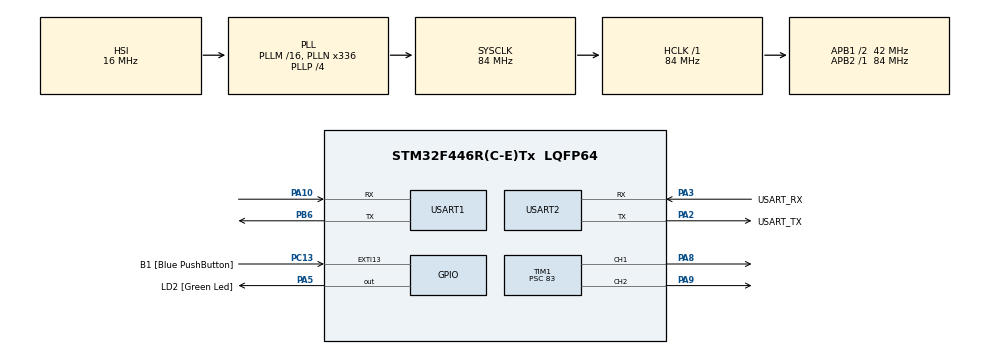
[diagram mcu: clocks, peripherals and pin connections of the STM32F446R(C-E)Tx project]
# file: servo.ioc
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Mcu.Family=STM32F4
Mcu.Name=STM32F446R(C-E)Tx
Mcu.Package=LQFP64
NVIC.PriorityGroup=NVIC_PRIORITYGROUP_0
PA10.Mode=Asynchronous
PA10.Signal=USART1_RX
PA13.GPIO_Label=TMS
PA13.Mode=Serial_Wire
PA13.Signal=SYS_JTMS-SWDIO
PA14.GPIO_Label=TCK
PA14.Mode=Serial_Wire
PA14.Signal=SYS_JTCK-SWCLK
PA2.GPIO_Label=USART_TX
PA2.GPIO_PuPd=GPIO_NOPULL
PA2.Mode=Asynchronous
PA2.Signal=USART2_TX
PA3.GPIO_Label=USART_RX
PA3.Mode=Asynchronous
PA3.Signal=USART2_RX
PA5.GPIO_Label=LD2 [Green Led]
PA5.Signal=GPIO_Output
PA8.Signal=S_TIM1_CH1
PA9.Signal=S_TIM1_CH2
PB3.GPIO_Label=SWO
PB3.Signal=SYS_JTDO-SWO
PB6.GPIO_PuPd=GPIO_PULLUP
PB6.Mode=Asynchronous
PB6.Signal=USART1_TX
PC13.GPIO_Label=B1 [Blue PushButton]
PC13.GPIO_ModeDefaultEXTI=GPIO_MODE_IT_FALLING
PC13.Signal=GPXTI13
PC14-OSC32_IN.Mode=LSE-External-Oscillator
PC14-OSC32_IN.Signal=RCC_OSC32_IN
PC15-OSC32_OUT.Mode=LSE-External-Oscillator
PC15-OSC32_OUT.Signal=RCC_OSC32_OUT
PH0-OSC_IN.Mode=HSE-External-Oscillator
PH0-OSC_IN.Signal=RCC_OSC_IN
PH1-OSC_OUT.Mode=HSE-External-Oscillator
PH1-OSC_OUT.Signal=RCC_OSC_OUT
ProjectManager.HeapSize=0x200
ProjectManager.StackSize=0x400
ProjectManager.TargetToolchain=STM32CubeIDE
RCC.48MHZClocksFreq_Value=84000000
RCC.AHBFreq_Value=84000000
RCC.APB1CLKDivider=RCC_HCLK_DIV2
RCC.APB1Freq_Value=42000000
RCC.APB1TimFreq_Value=84000000
RCC.APB2Freq_Value=84000000
RCC.APB2TimFreq_Value=84000000
RCC.CortexFreq_Value=84000000
RCC.FLatency-AdvancedSettings=FLASH_LATENCY_2
RCC.HCLKFreq_Value=84000000
RCC.HSE_VALUE=8000000
RCC.HSI_VALUE=16000000
RCC.PLLN=336
RCC.PLLP=RCC_PLLP_DIV4
RCC.SYSCLKFreq_VALUE=84000000
RCC.SYSCLKSource=RCC_SYSCLKSOURCE_PLLCLK
RCC.USBFreq_Value=168000000
RCC.VCOOutputFreq_Value=336000000
SH.S_TIM1_CH1.0=TIM1_CH1,PWM Generation1 CH1
SH.S_TIM1_CH2.0=TIM1_CH2,PWM Generation2 CH2
TIM1.Channel-PWM\ Generation1\ CH1=TIM_CHANNEL_1
TIM1.Channel-PWM\ Generation2\ CH2=TIM_CHANNEL_2
TIM1.Period=19999
TIM1.Prescaler=83
USART1.Parity=PARITY_EVEN
USART1.VirtualMode=VM_ASYNC
USART1.WordLength=WORDLENGTH_9B
USART2.Parity=PARITY_NONE
USART2.VirtualMode=VM_ASYNC
USART2.WordLength=WORDLENGTH_8B
board=NUCLEO-F446RE

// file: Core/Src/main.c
/* USER CODE BEGIN Header */
/**
  ******************************************************************************
  * @file           : main.c
  * @brief          : Main program body
  ******************************************************************************
  * @attention
  *
  * Copyright (c) 2026 STMicroelectronics.
  * All rights reserved.
  *
  * This software is licensed under terms that can be found in the LICENSE file
  * in the root directory of this software component.
  * If no LICENSE file comes with this software, it is provided AS-IS.
  *
  ******************************************************************************
  */
/* USER CODE END Header */
#include "main.h"

/* USER CODE BEGIN PD */
#define ICS_CMD_POS     0x87
#define ICS_POS_CENTER  7500 //3500 ~ 11500が範囲（可動域）
/* USER CODE END PD */

TIM_HandleTypeDef htim1;

UART_HandleTypeDef huart1;
UART_HandleTypeDef huart2;

/* USER CODE BEGIN PV */
int PWM = 1500;
int8_t step = 2;

/* USER CODE END PV */

void SystemClock_Config(void);
static void MX_GPIO_Init(void);
static void MX_USART2_UART_Init(void);
static void MX_USART1_UART_Init(void);
static void MX_TIM1_Init(void);

/* USER CODE BEGIN 0 */
/*void KRS_SetPosition(UART_HandleTypeDef *huart, uint8_t id, uint16_t pos) {
    uint8_t tx_buf[3];
    uint8_t dummy_rx[3];

    // サーボの可動範囲（3500〜11500）を超えないようにクランプ処理
    if (pos < 3500)  pos = 3500;
    if (pos > 11500) pos = 11500;

    // 14ビットのポジションデータを上位7ビット・下位7ビットに分解
    tx_buf[0] = ICS_CMD_POS | (id & 0x1F); // コマンドバイト (0x80 | ID)
    tx_buf[1] = (pos >> 7) & 0x7F;         // ポジション上位7ビット
    tx_buf[2] = pos & 0x7F;                // ポジション下位7ビット

    // 1線式半二重通信で3バイト送信 (タイムアウト10ms)
    HAL_UART_Transmit(huart, tx_buf, 0, 10);

    // 【重要】自分の投げた3バイトがそのままRXに返ってくるので、空読みしてバッファをクリア
    // これを怠ると、次回以降の受信処理やシリアルバッファが即座にオーバーフローします
    //HAL_UART_Receive(huart, dummy_rx, 0, 10);
}
*/
/* USER CODE END 0 */

int main(void)
{

  /* MCU Configuration--------------------------------------------------------*/

  /* Reset of all peripherals, Initializes the Flash interface and the Systick. */
  HAL_Init();

  /* Configure the system clock */
  SystemClock_Config();

  /* Initialize all configured peripherals */
  MX_GPIO_Init();
  MX_USART2_UART_Init();
  MX_USART1_UART_Init();
  MX_TIM1_Init();
  /* USER CODE BEGIN 2 */

  HAL_TIM_PWM_Start(&htim1, TIM_CHANNEL_1);
  __HAL_TIM_SET_COMPARE(&htim1, TIM_CHANNEL_1, 500);
  /* USER CODE END 2 */

  /* Infinite loop */
  /* USER CODE BEGIN WHILE */
  while (1)
  {
/*Serial	  // ID: 7 のサーボを少し左に傾ける (センター7500 - 1500)
	  KRS_SetPosition(&huart1, 7, 6000);
	  HAL_Delay(1000); // 1秒待機

	  // ID: 7 のサーボを少し右に傾ける (センター7500 + 1500)
	  KRS_SetPosition(&huart1, 7, 9000);
	  HAL_Delay(1000); // 1秒待機
*/

	  //sg92r
	  __HAL_TIM_SET_COMPARE(&htim1, TIM_CHANNEL_1, 550);
	  HAL_Delay(7000);
	  __HAL_TIM_SET_COMPARE(&htim1, TIM_CHANNEL_1, (950/90) * 80 + 550);
	  HAL_Delay(1000);
	  /*
	  __HAL_TIM_SET_COMPARE(&htim1, TIM_CHANNEL_1, 550);
	  HAL_Delay(5000);
	  __HAL_TIM_SET_COMPARE(&htim1, TIM_CHANNEL_1, (950/90) * 60 + 550);
	  HAL_Delay(5000);
		*/
	  //sg90-hv
	  /*
	  __HAL_TIM_SET_COMPARE(&htim1, TIM_CHANNEL_1, 1000);
	  HAL_Delay(10000);
	  __HAL_TIM_SET_COMPARE(&htim1, TIM_CHANNEL_1, 1500);
	  HAL_Delay(10000);
	  __HAL_TIM_SET_COMPARE(&htim1, TIM_CHANNEL_1, 2000);
	  HAL_Delay(10000);
	  __HAL_TIM_SET_COMPARE(&htim1, TIM_CHANNEL_1, 1500);
	  HAL_Delay(1000);
	  */
    /* USER CODE END WHILE */

  }
}

void SystemClock_Config(void)
{
  RCC_OscInitTypeDef RCC_OscInitStruct = {0};
  RCC_ClkInitTypeDef RCC_ClkInitStruct = {0};

  /** Configure the main internal regulator output voltage
  */
  __HAL_RCC_PWR_CLK_ENABLE();
  __HAL_PWR_VOLTAGESCALING_CONFIG(PWR_REGULATOR_VOLTAGE_SCALE3);

  /** Initializes the RCC Oscillators according to the specified parameters
  * in the RCC_OscInitTypeDef structure.
  */
  RCC_OscInitStruct.OscillatorType = RCC_OSCILLATORTYPE_HSI;
  RCC_OscInitStruct.HSIState = RCC_HSI_ON;
  RCC_OscInitStruct.HSICalibrationValue = RCC_HSICALIBRATION_DEFAULT;
  RCC_OscInitStruct.PLL.PLLState = RCC_PLL_ON;
  RCC_OscInitStruct.PLL.PLLSource = RCC_PLLSOURCE_HSI;
  RCC_OscInitStruct.PLL.PLLM = 16;
  RCC_OscInitStruct.PLL.PLLN = 336;
  RCC_OscInitStruct.PLL.PLLP = RCC_PLLP_DIV4;
  RCC_OscInitStruct.PLL.PLLQ = 2;
  RCC_OscInitStruct.PLL.PLLR = 2;
  if (HAL_RCC_OscConfig(&RCC_OscInitStruct) != HAL_OK)
  {
    Error_Handler();
  }

  /** Initializes the CPU, AHB and APB buses clocks
  */
  RCC_ClkInitStruct.ClockType = RCC_CLOCKTYPE_HCLK|RCC_CLOCKTYPE_SYSCLK
                              |RCC_CLOCKTYPE_PCLK1|RCC_CLOCKTYPE_PCLK2;
  RCC_ClkInitStruct.SYSCLKSource = RCC_SYSCLKSOURCE_PLLCLK;
  RCC_ClkInitStruct.AHBCLKDivider = RCC_SYSCLK_DIV1;
  RCC_ClkInitStruct.APB1CLKDivider = RCC_HCLK_DIV2;
  RCC_ClkInitStruct.APB2CLKDivider = RCC_HCLK_DIV1;

  if (HAL_RCC_ClockConfig(&RCC_ClkInitStruct, FLASH_LATENCY_2) != HAL_OK)
  {
    Error_Handler();
  }
}

static void MX_TIM1_Init(void)
{

  TIM_MasterConfigTypeDef sMasterConfig = {0};
  TIM_OC_InitTypeDef sConfigOC = {0};
  TIM_BreakDeadTimeConfigTypeDef sBreakDeadTimeConfig = {0};

  htim1.Instance = TIM1;
  htim1.Init.Prescaler = 83;
  htim1.Init.CounterMode = TIM_COUNTERMODE_UP;
  htim1.Init.Period = 19999;
  htim1.Init.ClockDivision = TIM_CLOCKDIVISION_DIV1;
  htim1.Init.RepetitionCounter = 0;
  htim1.Init.AutoReloadPreload = TIM_AUTORELOAD_PRELOAD_DISABLE;
  if (HAL_TIM_PWM_Init(&htim1) != HAL_OK)
  {
    Error_Handler();
  }
  sMasterConfig.MasterOutputTrigger = TIM_TRGO_RESET;
  sMasterConfig.MasterSlaveMode = TIM_MASTERSLAVEMODE_DISABLE;
  if (HAL_TIMEx_MasterConfigSynchronization(&htim1, &sMasterConfig) != HAL_OK)
  {
    Error_Handler();
  }
  sConfigOC.OCMode = TIM_OCMODE_PWM1;
  sConfigOC.Pulse = 0;
  sConfigOC.OCPolarity = TIM_OCPOLARITY_HIGH;
  sConfigOC.OCNPolarity = TIM_OCNPOLARITY_HIGH;
  sConfigOC.OCFastMode = TIM_OCFAST_DISABLE;
  sConfigOC.OCIdleState = TIM_OCIDLESTATE_RESET;
  sConfigOC.OCNIdleState = TIM_OCNIDLESTATE_RESET;
  if (HAL_TIM_PWM_ConfigChannel(&htim1, &sConfigOC, TIM_CHANNEL_1) != HAL_OK)
  {
    Error_Handler();
  }
  if (HAL_TIM_PWM_ConfigChannel(&htim1, &sConfigOC, TIM_CHANNEL_2) != HAL_OK)
  {
    Error_Handler();
  }
  sBreakDeadTimeConfig.OffStateRunMode = TIM_OSSR_DISABLE;
  sBreakDeadTimeConfig.OffStateIDLEMode = TIM_OSSI_DISABLE;
  sBreakDeadTimeConfig.LockLevel = TIM_LOCKLEVEL_OFF;
  sBreakDeadTimeConfig.DeadTime = 0;
  sBreakDeadTimeConfig.BreakState = TIM_BREAK_DISABLE;
  sBreakDeadTimeConfig.BreakPolarity = TIM_BREAKPOLARITY_HIGH;
  sBreakDeadTimeConfig.AutomaticOutput = TIM_AUTOMATICOUTPUT_DISABLE;
  if (HAL_TIMEx_ConfigBreakDeadTime(&htim1, &sBreakDeadTimeConfig) != HAL_OK)
  {
    Error_Handler();
  }
  HAL_TIM_MspPostInit(&htim1);

}

static void MX_USART1_UART_Init(void)
{

  huart1.Instance = USART1;
  huart1.Init.BaudRate = 115200;
  huart1.Init.WordLength = UART_WORDLENGTH_9B;
  huart1.Init.StopBits = UART_STOPBITS_1;
  huart1.Init.Parity = UART_PARITY_EVEN;
  huart1.Init.Mode = UART_MODE_TX_RX;
  huart1.Init.HwFlowCtl = UART_HWCONTROL_NONE;
  huart1.Init.OverSampling = UART_OVERSAMPLING_16;
  if (HAL_UART_Init(&huart1) != HAL_OK)
  {
    Error_Handler();
  }

}

static void MX_USART2_UART_Init(void)
{

  huart2.Instance = USART2;
  huart2.Init.BaudRate = 115200;
  huart2.Init.WordLength = UART_WORDLENGTH_8B;
  huart2.Init.StopBits = UART_STOPBITS_1;
  huart2.Init.Parity = UART_PARITY_NONE;
  huart2.Init.Mode = UART_MODE_TX_RX;
  huart2.Init.HwFlowCtl = UART_HWCONTROL_NONE;
  huart2.Init.OverSampling = UART_OVERSAMPLING_16;
  if (HAL_UART_Init(&huart2) != HAL_OK)
  {
    Error_Handler();
  }

}

static void MX_GPIO_Init(void)
{
  GPIO_InitTypeDef GPIO_InitStruct = {0};

  /* GPIO Ports Clock Enable */
  __HAL_RCC_GPIOC_CLK_ENABLE();
  __HAL_RCC_GPIOH_CLK_ENABLE();
  __HAL_RCC_GPIOA_CLK_ENABLE();
  __HAL_RCC_GPIOB_CLK_ENABLE();

  /*Configure GPIO pin Output Level */
  HAL_GPIO_WritePin(LD2_GPIO_Port, LD2_Pin, GPIO_PIN_RESET);

  /*Configure GPIO pin : B1_Pin */
  GPIO_InitStruct.Pin = B1_Pin;
  GPIO_InitStruct.Mode = GPIO_MODE_IT_FALLING;
  GPIO_InitStruct.Pull = GPIO_NOPULL;
  HAL_GPIO_Init(B1_GPIO_Port, &GPIO_InitStruct);

  /*Configure GPIO pin : LD2_Pin */
  GPIO_InitStruct.Pin = LD2_Pin;
  GPIO_InitStruct.Mode = GPIO_MODE_OUTPUT_PP;
  GPIO_InitStruct.Pull = GPIO_NOPULL;
  GPIO_InitStruct.Speed = GPIO_SPEED_FREQ_LOW;
  HAL_GPIO_Init(LD2_GPIO_Port, &GPIO_InitStruct);

}

void Error_Handler(void)
{
  __disable_irq();
  while (1)
  {
  }
}
